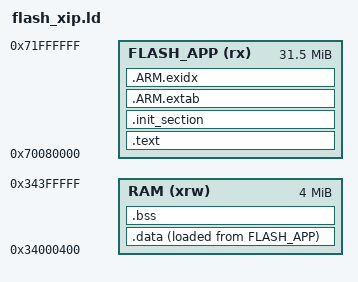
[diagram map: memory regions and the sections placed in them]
/****************************************************************************
 * boards/arm/stm32n6/atk-dnn647/scripts/flash_xip.ld
 *
 * SPDX-License-Identifier: Apache-2.0
 *
 * Licensed to the Apache Software Foundation (ASF) under one or more
 * contributor license agreements.  See the NOTICE file distributed with
 * this work for additional information regarding copyright ownership.  The
 * ASF licenses this file to you under the Apache License, Version 2.0 (the
 * "License"); you may not use this file except in compliance with the
 * License.  You may obtain a copy of the License at
 *
 *   http://www.apache.org/licenses/LICENSE-2.0
 *
 * Unless required by applicable law or agreed to in writing, software
 * distributed under the License is distributed on an "AS IS" BASIS, WITHOUT
 * WARRANTIES OR CONDITIONS OF ANY KIND, either express or implied.  See the
 * License for the specific language governing permissions and limitations
 * under the License.
 *
 ****************************************************************************/

/* XIP (Execute-In-Place) linker script for STM32N647X0.
 *
 * When the FSBL has initialized the XSPI flash controller and enabled
 * memory-mapped mode, the application code can run directly from external
 * flash at 0x70000000 (XIP).  Only .data, .bss, heap and stack need to
 * reside in SRAM.
 *
 * External flash layout (MX25UM25645G, 32MB):
 *   0x70000000 - 0x7007FFFF : FSBL (512K, includes boot header)
 *   0x70080000 - 0x70FFFFFF : Application (XIP)
 *
 * SRAM layout:
 *   0x34000400 - 0x343FFFFF : Application RAM (~4MB)
 */

MEMORY
{
    FLASH_APP (rx) : ORIGIN = 0x70080000, LENGTH = 32M - 512K
    RAM (xrw)      : ORIGIN = 0x34000400, LENGTH = 4193280
}

OUTPUT_ARCH(arm)
ENTRY(_stext)

SECTIONS
{
    .text : {
        _stext = ABSOLUTE(.);
        *(.vectors)
        *(.text .text.*)
        *(.fixup)
        *(.gnu.warning)
        *(.rodata .rodata.*)
        *(.gnu.linkonce.t.*)
        *(.glue_7)
        *(.glue_7t)
        *(.got)
        *(.gcc_except_table)
        *(.gnu.linkonce.r.*)
        _etext = ABSOLUTE(.);
    } > FLASH_APP

    .init_section : {
        _sinit = ABSOLUTE(.);
        KEEP(*(SORT_BY_INIT_PRIORITY(.init_array.*) SORT_BY_INIT_PRIORITY(.ctors.*)))
        KEEP(*(.init_array EXCLUDE_FILE(*crtbegin.o *crtbegin?.o *crtend.o *crtend?.o) .ctors))
        _einit = ABSOLUTE(.);
    } > FLASH_APP

    .ARM.extab : {
        *(.ARM.extab*)
    } > FLASH_APP

    __exidx_start = ABSOLUTE(.);
    .ARM.exidx : {
        *(.ARM.exidx*)
    } > FLASH_APP
    __exidx_end = ABSOLUTE(.);

    _eronly = ABSOLUTE(.);

    .data : {
        _sdata = ABSOLUTE(.);
        *(.data .data.*)
        *(.gnu.linkonce.d.*)
        CONSTRUCTORS
        . = ALIGN(4);
        _edata = ABSOLUTE(.);
    } > RAM AT > FLASH_APP

    .bss : {
        _sbss = ABSOLUTE(.);
        *(.bss .bss.*)
        *(.gnu.linkonce.b.*)
        *(COMMON)
        . = ALIGN(4);
        _ebss = ABSOLUTE(.);
    } > RAM

    /* Stabs debugging sections. */

    .stab 0 : { *(.stab) }
    .stabstr 0 : { *(.stabstr) }
    .stab.excl 0 : { *(.stab.excl) }
    .stab.exclstr 0 : { *(.stab.exclstr) }
    .stab.index 0 : { *(.stab.index) }
    .stab.indexstr 0 : { *(.stab.indexstr) }
    .comment 0 : { *(.comment) }
    .debug_abbrev 0 : { *(.debug_abbrev) }
    .debug_info 0 : { *(.debug_info) }
    .debug_line 0 : { *(.debug_line) }
    .debug_pubnames 0 : { *(.debug_pubnames) }
    .debug_aranges 0 : { *(.debug_aranges) }
}
